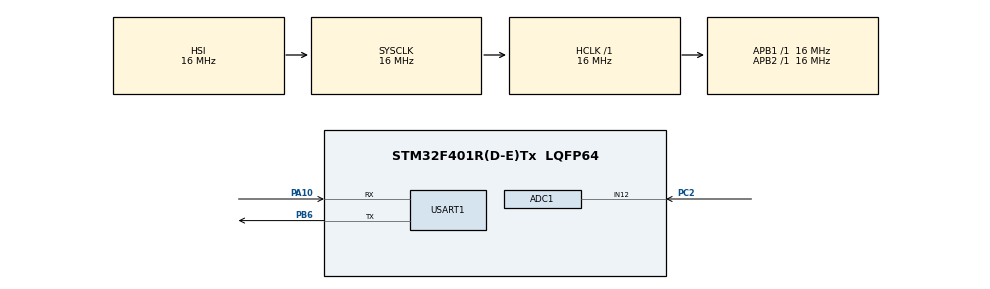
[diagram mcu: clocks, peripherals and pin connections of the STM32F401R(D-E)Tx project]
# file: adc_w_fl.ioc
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ADC1.Channel-1\#ChannelRegularConversion=ADC_CHANNEL_12
ADC1.NbrOfConversionFlag=1
ADC1.Rank-1\#ChannelRegularConversion=1
ADC1.SamplingTime-1\#ChannelRegularConversion=ADC_SAMPLETIME_3CYCLES
ADC1.master=1
Mcu.Family=STM32F4
Mcu.Name=STM32F401R(D-E)Tx
Mcu.Package=LQFP64
NVIC.PriorityGroup=NVIC_PRIORITYGROUP_4
PA10.Mode=Asynchronous
PA10.Signal=USART1_RX
PB6.Mode=Asynchronous
PB6.Signal=USART1_TX
PC2.Signal=ADCx_IN12
ProjectManager.HeapSize=0x200
ProjectManager.StackSize=0x400
ProjectManager.TargetToolchain=STM32CubeIDE
RCC.AHBFreq_Value=16000000
RCC.APB1Freq_Value=16000000
RCC.APB2Freq_Value=16000000
RCC.CortexFreq_Value=16000000
RCC.HSE_VALUE=25000000
RCC.HSI_VALUE=16000000
RCC.LSE_VALUE=32768
RCC.SYSCLKFreq_VALUE=16000000
RCC.VCOOutputFreq_Value=192000000
SH.ADCx_IN12.0=ADC1_IN12,IN12
USART1.VirtualMode=VM_ASYNC
board=custom

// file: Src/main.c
/* USER CODE BEGIN Header */
/**
  ******************************************************************************
  * @file           : main.c
  * @brief          : Main program body
  ******************************************************************************
  * @attention
  *
  * Copyright (c) 2026 STMicroelectronics.
  * All rights reserved.
  *
  * This software is licensed under terms that can be found in the LICENSE file
  * in the root directory of this software component.
  * If no LICENSE file comes with this software, it is provided AS-IS.
  *
  ******************************************************************************
  */
/* USER CODE END Header */
#include "main.h"
/* USER CODE BEGIN Includes */
#include <stdio.h>
#include <string.h>
/* USER CODE END Includes */

/* USER CODE BEGIN PD */

#define window_size 10

/* USER CODE END PD */

ADC_HandleTypeDef hadc1;

UART_HandleTypeDef huart1;

int gate;

static uint16_t adc_buffer[window_size], adc_avg, sample_count, idx, adc_sum;

void SystemClock_Config(void);
static void MX_GPIO_Init(void);
static void MX_ADC1_Init(void);
static void MX_USART1_UART_Init(void);

/* USER CODE BEGIN 0 */

void ADC_SmplAvg(void)
{
    uint16_t new_sample;

    if (HAL_ADC_Start(&hadc1) != HAL_OK)  // initialize adc1
    {
        Error_Handler();
    }
    if (HAL_ADC_PollForConversion(&hadc1, 10) != HAL_OK)  // wait for specified time to get the adc vlue by polling delay
    {
        HAL_ADC_Stop(&hadc1);
        return;
    }

    new_sample = (uint16_t)HAL_ADC_GetValue(&hadc1);  // record the obtained adc value
    HAL_ADC_Stop(&hadc1);

    if (sample_count == window_size)
    {
        adc_sum -= adc_buffer[idx];  // if more than 10 values added, remove the next round of matching values circularly
    }
    else
    {
        sample_count++;
    }

    adc_buffer[idx++] = new_sample;
    adc_sum += new_sample;
    if (idx >= window_size)
    {
    	idx = 0;
    }
    if (sample_count == window_size)
    {
        adc_avg = (uint16_t)(adc_sum / window_size);  // average of 10 values
        gate = 1;  // release the transmitting block to send through uart
    }
}

const char *HAL_err_to_name(HAL_StatusTypeDef status)  // to translate the status to readable string
{
    switch (status)
    {
        case HAL_OK:
            return "HAL_OK";

        case HAL_ERROR:
            return "HAL_ERROR";

        case HAL_BUSY:
            return "HAL_BUSY";

        case HAL_TIMEOUT:
            return "HAL_TIMEOUT";

        default:
            return "HAL_STATUS_UNKNOWN";
    }
}
/* USER CODE END 0 */

int main(void)
{

  /* MCU Configuration--------------------------------------------------------*/

  /* Reset of all peripherals, Initializes the Flash interface and the Systick. */
  HAL_Init();

  /* Configure the system clock */
  SystemClock_Config();

  /* Initialize all configured peripherals */
  MX_GPIO_Init();
  MX_ADC1_Init();
  MX_USART1_UART_Init();

  /* Infinite loop */
  /* USER CODE BEGIN WHILE */
  uint32_t last = 0;  // record the last checkpoint of time

  while (1)
  {
	  uint32_t current = HAL_GetTick();  // record the current timestamp
	  if (current - last >= 100)
	  {
		  last = current;  // replace the last with current, to push the delay to upper limits
		  ADC_SmplAvg();  // mechanism to sample and pickup average from 10 samples at an interval of 100 ms
		  if (gate)
		  {
			  uint8_t string[54] = {0};
			  int len = sprintf((char *)string, "ADC value : %u\n", adc_avg);
			  HAL_StatusTypeDef st = HAL_UART_Transmit(&huart1, string, len, 10);  // transmit the adc value as a string through uart
			  if (st != HAL_OK)
			  {
				  printf("error in transmitting data\nerror = %s\n", HAL_err_to_name(st));
			  }
		  }
	  }
  }
}
/* USER CODE END 3 */

void SystemClock_Config(void)
{
  RCC_OscInitTypeDef RCC_OscInitStruct = {0};
  RCC_ClkInitTypeDef RCC_ClkInitStruct = {0};

  /** Configure the main internal regulator output voltage
  */
  __HAL_RCC_PWR_CLK_ENABLE();
  __HAL_PWR_VOLTAGESCALING_CONFIG(PWR_REGULATOR_VOLTAGE_SCALE2);

  /** Initializes the RCC Oscillators according to the specified parameters
  * in the RCC_OscInitTypeDef structure.
  */
  RCC_OscInitStruct.OscillatorType = RCC_OSCILLATORTYPE_HSI;
  RCC_OscInitStruct.HSIState = RCC_HSI_ON;
  RCC_OscInitStruct.HSICalibrationValue = RCC_HSICALIBRATION_DEFAULT;
  RCC_OscInitStruct.PLL.PLLState = RCC_PLL_NONE;
  if (HAL_RCC_OscConfig(&RCC_OscInitStruct) != HAL_OK)
  {
    Error_Handler();
  }

  /** Initializes the CPU, AHB and APB buses clocks
  */
  RCC_ClkInitStruct.ClockType = RCC_CLOCKTYPE_HCLK|RCC_CLOCKTYPE_SYSCLK
                              |RCC_CLOCKTYPE_PCLK1|RCC_CLOCKTYPE_PCLK2;
  RCC_ClkInitStruct.SYSCLKSource = RCC_SYSCLKSOURCE_HSI;
  RCC_ClkInitStruct.AHBCLKDivider = RCC_SYSCLK_DIV1;
  RCC_ClkInitStruct.APB1CLKDivider = RCC_HCLK_DIV1;
  RCC_ClkInitStruct.APB2CLKDivider = RCC_HCLK_DIV1;

  if (HAL_RCC_ClockConfig(&RCC_ClkInitStruct, FLASH_LATENCY_0) != HAL_OK)
  {
    Error_Handler();
  }
}

static void MX_ADC1_Init(void)
{

  ADC_ChannelConfTypeDef sConfig = {0};

  /** Configure the global features of the ADC (Clock, Resolution, Data Alignment and number of conversion)
  */
  hadc1.Instance = ADC1;
  hadc1.Init.ClockPrescaler = ADC_CLOCK_SYNC_PCLK_DIV2;
  hadc1.Init.Resolution = ADC_RESOLUTION_12B;
  hadc1.Init.ScanConvMode = DISABLE;
  hadc1.Init.ContinuousConvMode = DISABLE;
  hadc1.Init.DiscontinuousConvMode = DISABLE;
  hadc1.Init.ExternalTrigConvEdge = ADC_EXTERNALTRIGCONVEDGE_NONE;
  hadc1.Init.ExternalTrigConv = ADC_SOFTWARE_START;
  hadc1.Init.DataAlign = ADC_DATAALIGN_RIGHT;
  hadc1.Init.NbrOfConversion = 1;
  hadc1.Init.DMAContinuousRequests = DISABLE;
  hadc1.Init.EOCSelection = ADC_EOC_SINGLE_CONV;
  if (HAL_ADC_Init(&hadc1) != HAL_OK)
  {
    Error_Handler();
  }

  /** Configure for the selected ADC regular channel its corresponding rank in the sequencer and its sample time.
  */
  sConfig.Channel = ADC_CHANNEL_12;
  sConfig.Rank = 1;
  sConfig.SamplingTime = ADC_SAMPLETIME_3CYCLES;
  if (HAL_ADC_ConfigChannel(&hadc1, &sConfig) != HAL_OK)
  {
    Error_Handler();
  }

}

static void MX_USART1_UART_Init(void)
{

  huart1.Instance = USART1;
  huart1.Init.BaudRate = 115200;
  huart1.Init.WordLength = UART_WORDLENGTH_8B;
  huart1.Init.StopBits = UART_STOPBITS_1;
  huart1.Init.Parity = UART_PARITY_NONE;
  huart1.Init.Mode = UART_MODE_TX_RX;
  huart1.Init.HwFlowCtl = UART_HWCONTROL_NONE;
  huart1.Init.OverSampling = UART_OVERSAMPLING_16;
  if (HAL_UART_Init(&huart1) != HAL_OK)
  {
    Error_Handler();
  }

}

static void MX_GPIO_Init(void)
{

  /* GPIO Ports Clock Enable */
  __HAL_RCC_GPIOC_CLK_ENABLE();
  __HAL_RCC_GPIOA_CLK_ENABLE();
  __HAL_RCC_GPIOB_CLK_ENABLE();

}

void Error_Handler(void)
{
  /* USER CODE BEGIN Error_Handler_Debug */
  /* User can add his own implementation to report the HAL error return state */
  __disable_irq();
  while (1)
  {
	  printf("hal level failure\ncheck for components or initializations\n");
	  HAL_Delay(100);
  }
  /* USER CODE END Error_Handler_Debug */
}
